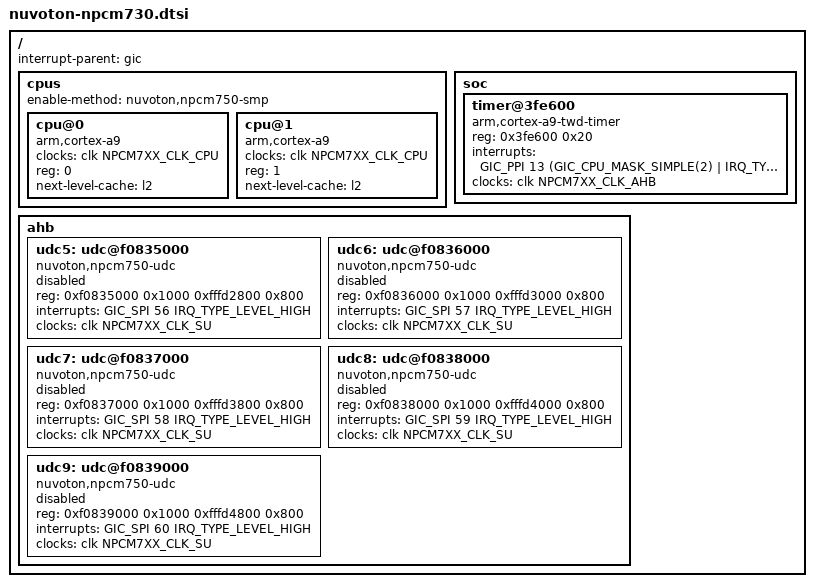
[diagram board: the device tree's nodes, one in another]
// SPDX-License-Identifier: GPL-2.0
// Copyright (c) 2020 Nuvoton Technology

#include "nuvoton-common-npcm7xx.dtsi"

/ {
	#address-cells = <1>;
	#size-cells = <1>;
	interrupt-parent = <&gic>;

	cpus {
		#address-cells = <1>;
		#size-cells = <0>;
		enable-method = "nuvoton,npcm750-smp";

		cpu@0 {
			device_type = "cpu";
			compatible = "arm,cortex-a9";
			clocks = <&clk NPCM7XX_CLK_CPU>;
			clock-names = "clk_cpu";
			reg = <0>;
			next-level-cache = <&l2>;
		};

		cpu@1 {
			device_type = "cpu";
			compatible = "arm,cortex-a9";
			clocks = <&clk NPCM7XX_CLK_CPU>;
			clock-names = "clk_cpu";
			reg = <1>;
			next-level-cache = <&l2>;
		};
	};

	soc {
		timer@3fe600 {
			compatible = "arm,cortex-a9-twd-timer";
			reg = <0x3fe600 0x20>;
			interrupts = <GIC_PPI 13 (GIC_CPU_MASK_SIMPLE(2) |
						  IRQ_TYPE_LEVEL_HIGH)>;
			clocks = <&clk NPCM7XX_CLK_AHB>;
		};
	};

	ahb {
		udc5: udc@f0835000 {
			compatible = "nuvoton,npcm750-udc";
			reg = <0xf0835000 0x1000
			       0xfffd2800 0x800>;
			interrupts = <GIC_SPI 56 IRQ_TYPE_LEVEL_HIGH>;
			status = "disabled";
			clocks = <&clk NPCM7XX_CLK_SU>;
			clock-names = "clk_usb_bridge";
		};

		udc6: udc@f0836000 {
			compatible = "nuvoton,npcm750-udc";
			reg = <0xf0836000 0x1000
			       0xfffd3000 0x800>;
			interrupts = <GIC_SPI 57 IRQ_TYPE_LEVEL_HIGH>;
			status = "disabled";
			clocks = <&clk NPCM7XX_CLK_SU>;
			clock-names = "clk_usb_bridge";
		};

		udc7: udc@f0837000 {
			compatible = "nuvoton,npcm750-udc";
			reg = <0xf0837000 0x1000
			       0xfffd3800 0x800>;
			interrupts = <GIC_SPI 58 IRQ_TYPE_LEVEL_HIGH>;
			status = "disabled";
			clocks = <&clk NPCM7XX_CLK_SU>;
			clock-names = "clk_usb_bridge";
		};

		udc8: udc@f0838000 {
			compatible = "nuvoton,npcm750-udc";
			reg = <0xf0838000 0x1000
			       0xfffd4000 0x800>;
			interrupts = <GIC_SPI 59 IRQ_TYPE_LEVEL_HIGH>;
			status = "disabled";
			clocks = <&clk NPCM7XX_CLK_SU>;
			clock-names = "clk_usb_bridge";
		};

		udc9: udc@f0839000 {
			compatible = "nuvoton,npcm750-udc";
			reg = <0xf0839000 0x1000
			       0xfffd4800 0x800>;
			interrupts = <GIC_SPI 60 IRQ_TYPE_LEVEL_HIGH>;
			status = "disabled";
			clocks = <&clk NPCM7XX_CLK_SU>;
			clock-names = "clk_usb_bridge";
		};
	};
};
